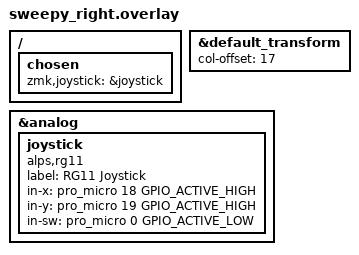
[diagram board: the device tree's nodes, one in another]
/*
 * Copyright (c) 2020 The ZMK Contributors
 *
 * SPDX-License-Identifier: MIT
 */

#include "sweepy.dtsi"

&default_transform {
    col-offset = <17>;
};
/ {
    chosen {
        zmk,joystick = &joystick;
    };
};

&analog {
    status = "okay";
    
    joystick: joystick {
        compatible = "alps,rg11";
        label = "RG11 Joystick";
        
        // Укажи пины к которым подключен джойстик
        in-x = <&pro_micro 18 GPIO_ACTIVE_HIGH>;  // A0 - URX
        in-y = <&pro_micro 19 GPIO_ACTIVE_HIGH>;  // A1 - URY  
        in-sw = <&pro_micro 0 GPIO_ACTIVE_LOW>;   // D0 - SW
    };
};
